# APM32F445 register map
File version: 1.0
CPU: CM4 r0p1, little endian, MPU, FPU, 4 interrupt priority bits
Registers are 32-bit, read-write, reset 0x0 unless marked. A register's access mark holds for its fields unless they carry their own. Offsets are from the block's base; [hi:lo] are bit positions; {n}, {i} and the like mark numbered series; 'fields as' and 'values as' point back to an identical list.

## CFGIO — Configurable Communication Interface
Base 0x4005A000
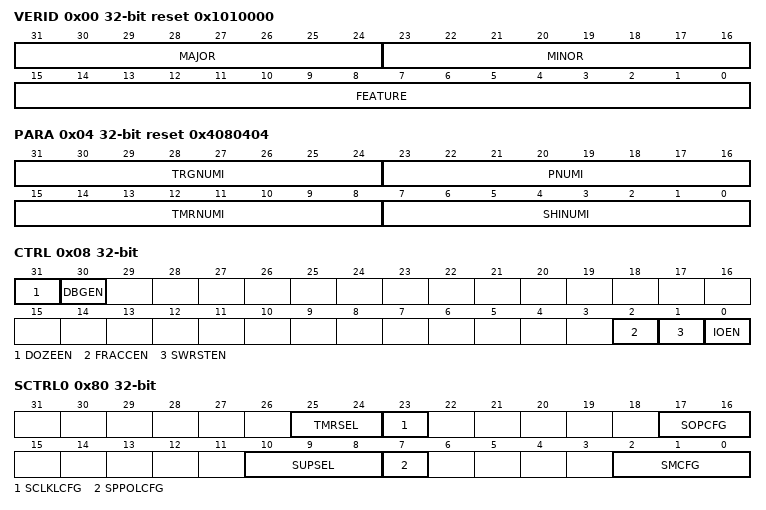
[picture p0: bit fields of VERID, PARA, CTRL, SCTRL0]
0x00 VERID ro reset 0x1010000 — Version ID Register
  [31:24] MAJOR — Major Version Number
  [23:16] MINOR — Minor Version Number
  [15:0] FEATURE — Feature Number
    0=Standard features implemented; 1=Supports state, logic and parallel modes
0x04 PARA ro reset 0x4080404 — Parameter Register
  [31:24] TRGNUMI — Trigger Number Implemented
  [23:16] PNUMI — Pin Number Implemented
  [15:8] TMRNUMI — Timer Number Implemented
  [7:0] SHINUMI — Shifter Number Implemented
0x08 CTRL — Control Register
  [31] DOZEEN — In Doze Mode IO Enable
    0=CFGIO enabled in Doze modes; 1=CFGIO disabled in Doze modes
  [30] DBGEN — In Debug Mode IO Enable
    0=CFGIO is disabled in debug modes; 1=CFGIO is enabled in debug modes
  [2] FRACCEN — Fast Register Access Enable
    0=Configures for normal register accesses to CFGIO; 1=Configures for fast register accesses to CFGIO
  [1] SWRSTEN — Software Reset Enable
    0=Software reset is disabled; 1=Software reset is enabled, all CFGIO registers except the Control Register are reset
  [0] IOEN — IO Module Enable
    0=CFGIO module is disabled; 1=CFGIO module is enabled
0x0C PIDATA ro — Pin Input Data Register
  [7:0] PIDATA — Pin Input Data
0x10 SSTS — Shifter Status Register
  [3:0] SSTS — Shifter Status
0x14 SERRFLG — Shifter Error Flags Register
  [3:0] SERRFLG — Shifter Error Flag
0x18 TMRSTS — Timer Status Register
  [3:0] TMRSTS — Timer Status
0x20 SSTSIEN — Shifter Status Interrupt Enable Register
  [3:0] SSTSIEN — Shifter Status Interrupt Enable
0x24 SEFIEN — Shifter Error Flag Interrupt Enable Register
  [3:0] SEFIEN — Shifter Error Flag Interrupt Enable
0x28 TMRSTSIEN — Timer Status Interrupt Enable Register
  [3:0] TMRSTSIEN — Timer Status Interrupt Enable
0x30 DMAREQEN — Shifter Status DMA request Enable Register
  [3:0] DMAREQEN — Shifter Status DMA Request Enable
0x80 SCTRL0 — Shifter Control Register 0
  [25:24] TMRSEL — (Timer Select)
  [23] SCLKLCFG — Shift clock location Configure
    0=Shift on posedge of Shift clock; 1=Shift on negedge of Shift clock
  [17:16] SOPCFG — Shifter Output Pin Configure
    0=Shifter pin output disabled; 1=Shifter pin open drain or bidirectional output enable; 2=Shifter pin bidirectional output data; 3=Shifter pin output
  [10:8] SUPSEL — Shifter Use Pin Select
  [7] SPPOLCFG — Shifter Pin Polarity Configure
    0=Pin is active high; 1=Pin is active low
  [2:0] SMCFG — Shifter Mode Configure
    0=Disabled; 1=Receive mode. Captures the current Shifter content into the SBUFDATA on expiration of the Timer.; 2=Transmit mode. Load SBUFDATA contents into the Shifter on expiration of the Timer.; 4=Match Store mode. Shifter data is compared to SBUFDATA content on expiration of the Timer.; 5=Match Continuous mode. Shifter data is continuously compared to SBUFDATA contents.
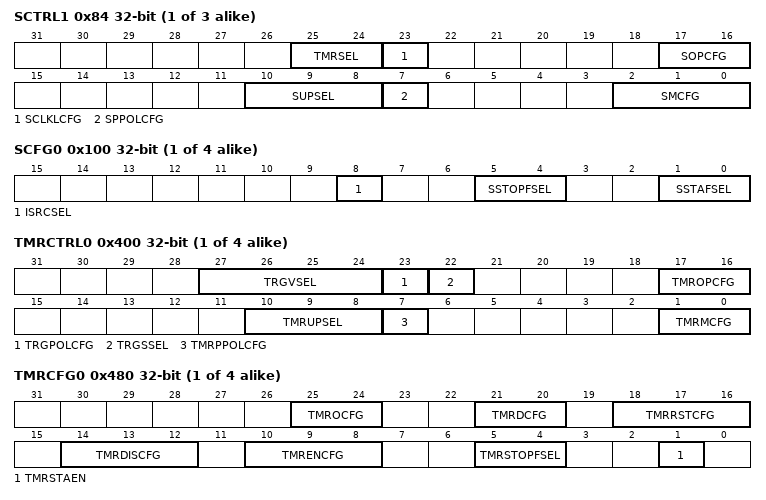
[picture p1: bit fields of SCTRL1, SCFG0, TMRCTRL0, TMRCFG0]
{0x80+4i} SCTRL{i} (i=1..3) — Shifter Control Register {i}
  [25:24] TMRSEL — (Timer Select)
  [23] SCLKLCFG — Shift clock location Configuration
    values as SCTRL0.SCLKLCFG
  [17:16] SOPCFG — Shifter Output Pin Configuration
    values as SCTRL0.SOPCFG
  [10:8] SUPSEL — Shifter Use Pin Select
  [7] SPPOLCFG — Shifter Pin Polarity Configuration
    0=Pin is active high; 1=Pin is active low
  [2:0] SMCFG — Shifter Mode Configuration
    values as SCTRL0.SMCFG
{0x100+4i} SCFG{i} (i=0..3) — Shifter Configure Register {i}
  [8] ISRCSEL — Input Source Select
    0=Pin; 1=Shifter N+1 Output
  [5:4] SSTOPFSEL — Shifter Stop Bit Function Select
    0=Stop bit disabled for transmitter/receiver/match store; 1=Reserved for transmitter/receiver/match store; 2=Transmitter outputs stop bit value 0 on store, receiver/match store sets error flag if stop bit is not 0; 3=Transmitter outputs stop bit value 1 on store, receiver/match store sets error flag if stop bit is not 1
  [1:0] SSTAFSEL — Shifter Start Bit Function Select
    0=Start bit disabled for transmitter/receiver/match store, transmitter loads data on enable; 1=Start bit disabled for transmitter/receiver/match store, transmitter loads data on first shift; 2=Transmitter outputs start bit value 0 before loading data on first shift, receiver/match store sets error flag if start bit is not 0; 3=Transmitter outputs start bit value 1 before loading data on first shift, receiver/match store sets error flag if start bit is not 1
{0x200+4i} SBUF{i} (i=0..3) — Shifter Buffer Register {i}
  [31:0] SBUFDATA — Shift Buffer Data
{0x280+4i} SBUFBITSWA{i} (i=0..3) — Shifter Buffer {i} Bit Swapped Register
  [31:0] BITSWA — Bit Swap
{0x300+4i} SBUFBYTSWA{i} (i=0..3) — Shifter Buffer{i} Byte Swapped Register
  [31:0] BYTSWA — Byte Swap
{0x380+4i} SBUFBSWA{i} (i=0..3) — Shifter Buffer{i} Bit Byte Swapped Register
  [31:0] BSWAWEB — Bit Swapped Within Each Byte
{0x400+4i} TMRCTRL{i} (i=0..3) — Timer Control Register {i}
  [27:24] TRGVSEL — Trigger Valid Value Select
  [23] TRGPOLCFG — Trigger Polarity Configure
    0=Trigger active high; 1=Trigger active low
  [22] TRGSSEL — Trigger Source Select
    0=External trigger selected; 1=Internal trigger selected
  [17:16] TMROPCFG — Timer output Pin Configure
    0=Timer pin output disabled; 1=Timer pin open drain or bidirectional output enable; 2=Timer pin bidirectional output data; 3=Timer pin output
  [10:8] TMRUPSEL — Timer Use Pin Select
  [7] TMRPPOLCFG — Timer Pin Polarity Configure
    0=Pin is active high; 1=Pin is active low
  [1:0] TMRMCFG — Timer Mode Configure
    0=Timer Disabled; 1=Dual 8-bit counters baud/bit mode; 2=Dual 8-bit counters PWM mode; 3=Single 16-bit counter mode
{0x480+4i} TMRCFG{i} (i=0..3) — Timer Configure Register {i}
  [25:24] TMROCFG — Timer Output Configure
    0=Timer output is logic one when enabled and is not affected by timer reset; 1=Timer output is logic zero when enabled and is not affected by timer reset; 2=Timer output is logic one when enabled and on timer reset; 3=Timer output is logic zero when enabled and on timer reset
  [21:20] TMRDCFG — Timer Decrement Configure
    0=Decrement counter on CFGIO clock, Shift clock equals Timer output; 1=Decrement counter on Trigger input (both edges), Shift clock equals Timer output; 2=Decrement counter on Pin input (both edges), Shift clock equals Pin input; 3=Decrement counter on Trigger input (both edges), Shift clock equals Trigger input
  [18:16] TMRRSTCFG — Timer Reset Condition Configure
    0=Timer never reset; 2=Timer reset on Timer Pin equal to Timer Output; 3=Timer reset on Timer Trigger equal to Timer Output; 4=Timer reset on Timer Pin rising edge; 6=Timer reset on Trigger rising edge; 7=Timer reset on Trigger rising or falling edge
  [14:12] TMRDISCFG — Timer Disable Condition Configure
    0=Timer never disabled; 1=Timer disabled on Timer N-1 disable; 2=Timer disabled on Timer compare; 3=Timer disabled on Timer compare and Trigger Low; 4=Timer disabled on Pin rising or falling edge; 5=Timer disabled on Pin rising or falling edge provided Trigger is high; 6=Timer disabled on Trigger falling edge
  [10:8] TMRENCFG — Timer Enable Condition Configure
    0=Timer always enabled; 1=Timer enabled on Timer N-1 enable; 2=Timer enabled on Trigger high; 3=Timer enabled on Trigger high and Pin high; 4=Timer enabled on Pin rising edge; 5=Timer enabled on Pin rising edge and Trigger high; 6=Timer enabled on Trigger rising edge; 7=Timer enabled on Trigger rising or falling edge
  [5:4] TMRSTOPFSEL — Timer Stop Bit function select
    0=Stop bit disabled; 1=Stop bit is enabled on timer compare; 2=Stop bit is enabled on timer disable; 3=Stop bit is enabled on timer compare and timer disable
  [1] TMRSTAEN — Timer Start Bit Enable
    0=Start bit disabled; 1=Start bit enabled
{0x500+4i} TMRCOMP{i} (i=0..3) — Timer Compare Register {i}
  [15:0] TMRCOMPV — Timer Compare Value
